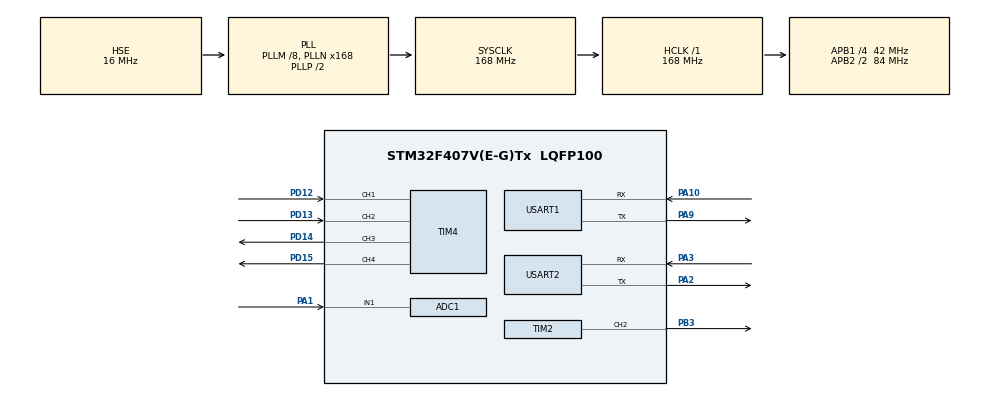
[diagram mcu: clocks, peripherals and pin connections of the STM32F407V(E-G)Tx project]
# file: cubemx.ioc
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ADC1.Channel-1\#ChannelRegularConversion=ADC_CHANNEL_1
ADC1.NbrOfConversionFlag=1
ADC1.Rank-1\#ChannelRegularConversion=1
ADC1.SamplingTime-1\#ChannelRegularConversion=ADC_SAMPLETIME_3CYCLES
ADC1.master=1
Mcu.Family=STM32F4
Mcu.Name=STM32F407V(E-G)Tx
Mcu.Package=LQFP100
NVIC.PriorityGroup=NVIC_PRIORITYGROUP_4
PA0-WKUP.Signal=S_TIM2_CH1_ETR
PA1.Signal=ADCx_IN1
PA10.Mode=Asynchronous
PA10.Signal=USART1_RX
PA13.Mode=Serial_Wire
PA13.Signal=SYS_JTMS-SWDIO
PA14.Mode=Serial_Wire
PA14.Signal=SYS_JTCK-SWCLK
PA2.Mode=Asynchronous
PA2.Signal=USART2_TX
PA3.Mode=Asynchronous
PA3.Signal=USART2_RX
PA9.Mode=Asynchronous
PA9.Signal=USART1_TX
PB3.Signal=S_TIM2_CH2
PD12.Signal=S_TIM4_CH1
PD13.Signal=S_TIM4_CH2
PD14.Signal=S_TIM4_CH3
PD15.Signal=S_TIM4_CH4
PH0-OSC_IN.Mode=HSE-External-Oscillator
PH0-OSC_IN.Signal=RCC_OSC_IN
PH1-OSC_OUT.Mode=HSE-External-Oscillator
PH1-OSC_OUT.Signal=RCC_OSC_OUT
ProjectManager.HeapSize=0x200
ProjectManager.StackSize=0x400
ProjectManager.TargetToolchain=EWARM V8.50
RCC.48MHZClocksFreq_Value=84000000
RCC.AHBFreq_Value=168000000
RCC.APB1CLKDivider=RCC_HCLK_DIV4
RCC.APB1Freq_Value=42000000
RCC.APB1TimFreq_Value=84000000
RCC.APB2CLKDivider=RCC_HCLK_DIV2
RCC.APB2Freq_Value=84000000
RCC.APB2TimFreq_Value=168000000
RCC.CortexFreq_Value=168000000
RCC.HCLKFreq_Value=168000000
RCC.HSE_VALUE=16000000
RCC.HSI_VALUE=16000000
RCC.LSE_VALUE=32768
RCC.PLLM=8
RCC.PLLN=168
RCC.PLLSourceVirtual=RCC_PLLSOURCE_HSE
RCC.RCC_MCO1Source=RCC_MCO1SOURCE_PLLCLK
RCC.RCC_MCO2Source=RCC_MCO2SOURCE_PLLCLK
RCC.SYSCLKFreq_VALUE=168000000
RCC.SYSCLKSource=RCC_SYSCLKSOURCE_PLLCLK
RCC.VCOOutputFreq_Value=336000000
SH.ADCx_IN1.0=ADC1_IN1,IN1
SH.S_TIM2_CH1_ETR.0=TIM2_CH1
SH.S_TIM2_CH2.0=TIM2_CH2,PWM Generation2 CH2
SH.S_TIM4_CH1.0=TIM4_CH1,Encoder_Interface
SH.S_TIM4_CH2.0=TIM4_CH2,Encoder_Interface
SH.S_TIM4_CH3.0=TIM4_CH3,PWM Generation3 CH3
SH.S_TIM4_CH4.0=TIM4_CH4,PWM Generation4 CH4
TIM11.AutoReloadPreload=TIM_AUTORELOAD_PRELOAD_ENABLE
TIM11.Period=100-1
TIM2.Channel-PWM\ Generation2\ CH2=TIM_CHANNEL_2
TIM4.Channel-PWM\ Generation3\ CH3=TIM_CHANNEL_3
TIM4.Channel-PWM\ Generation4\ CH4=TIM_CHANNEL_4
USART1.VirtualMode=VM_ASYNC
USART2.VirtualMode=VM_ASYNC
VP_TIM11_VS_ClockSourceINT.Mode=Enable_Timer
VP_TIM13_VS_ClockSourceINT.Mode=Enable_Timer
VP_TIM2_VS_ClockSourceINT.Mode=Internal
VP_TIM3_VS_ClockSourceINT.Mode=Internal
board=custom

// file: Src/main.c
/* USER CODE BEGIN Header */
/**
  ******************************************************************************
  * @file           : main.c
  * @brief          : Main program body
  ******************************************************************************
  * @attention
  *
  * Copyright (c) 2024 STMicroelectronics.
  * All rights reserved.
  *
  * This software is licensed under terms that can be found in the LICENSE file
  * in the root directory of this software component.
  * If no LICENSE file comes with this software, it is provided AS-IS.
  *
  ******************************************************************************
  */
/* USER CODE END Header */
#include "main.h"

ADC_HandleTypeDef hadc1;

TIM_HandleTypeDef htim2;
TIM_HandleTypeDef htim3;
TIM_HandleTypeDef htim4;
TIM_HandleTypeDef htim11;
TIM_HandleTypeDef htim13;

UART_HandleTypeDef huart1;
UART_HandleTypeDef huart2;

void SystemClock_Config(void);
static void MX_GPIO_Init(void);
static void MX_TIM2_Init(void);
static void MX_USART1_UART_Init(void);
static void MX_TIM3_Init(void);
static void MX_USART2_UART_Init(void);
static void MX_ADC1_Init(void);
static void MX_TIM11_Init(void);
static void MX_TIM13_Init(void);
static void MX_TIM4_Init(void);

__WEAK int main(void)
{

  /* USER CODE BEGIN 1 */
////////
  /* USER CODE END 1 */

  /* MCU Configuration--------------------------------------------------------*/

  /* Reset of all peripherals, Initializes the Flash interface and the Systick. */
  HAL_Init();

  /* USER CODE BEGIN Init */
////////
  /* USER CODE END Init */

  /* Configure the system clock */
  SystemClock_Config();

  /* USER CODE BEGIN SysInit */
////////
  /* USER CODE END SysInit */

  /* Initialize all configured peripherals */
  MX_GPIO_Init();
  MX_TIM2_Init();
  MX_USART1_UART_Init();
  MX_TIM3_Init();
  MX_USART2_UART_Init();
  MX_ADC1_Init();
  MX_TIM11_Init();
  MX_TIM13_Init();
  MX_TIM4_Init();
  /* USER CODE BEGIN 2 */
////////
  /* USER CODE END 2 */

  /* Infinite loop */
  /* USER CODE BEGIN WHILE */
////////  while (1)
////////  {
    /* USER CODE END WHILE */

    /* USER CODE BEGIN 3 */
////////  }
  /* USER CODE END 3 */
}

void SystemClock_Config(void)
{
  RCC_OscInitTypeDef RCC_OscInitStruct = {0};
  RCC_ClkInitTypeDef RCC_ClkInitStruct = {0};

  /** Configure the main internal regulator output voltage
  */
  __HAL_RCC_PWR_CLK_ENABLE();
  __HAL_PWR_VOLTAGESCALING_CONFIG(PWR_REGULATOR_VOLTAGE_SCALE1);

  /** Initializes the RCC Oscillators according to the specified parameters
  * in the RCC_OscInitTypeDef structure.
  */
  RCC_OscInitStruct.OscillatorType = RCC_OSCILLATORTYPE_HSE;
  RCC_OscInitStruct.HSEState = RCC_HSE_ON;
  RCC_OscInitStruct.PLL.PLLState = RCC_PLL_ON;
  RCC_OscInitStruct.PLL.PLLSource = RCC_PLLSOURCE_HSE;
  RCC_OscInitStruct.PLL.PLLM = 8;
  RCC_OscInitStruct.PLL.PLLN = 168;
  RCC_OscInitStruct.PLL.PLLP = RCC_PLLP_DIV2;
  RCC_OscInitStruct.PLL.PLLQ = 4;
  if (HAL_RCC_OscConfig(&RCC_OscInitStruct) != HAL_OK)
  {
    Error_Handler();
  }

  /** Initializes the CPU, AHB and APB buses clocks
  */
  RCC_ClkInitStruct.ClockType = RCC_CLOCKTYPE_HCLK|RCC_CLOCKTYPE_SYSCLK
                              |RCC_CLOCKTYPE_PCLK1|RCC_CLOCKTYPE_PCLK2;
  RCC_ClkInitStruct.SYSCLKSource = RCC_SYSCLKSOURCE_PLLCLK;
  RCC_ClkInitStruct.AHBCLKDivider = RCC_SYSCLK_DIV1;
  RCC_ClkInitStruct.APB1CLKDivider = RCC_HCLK_DIV4;
  RCC_ClkInitStruct.APB2CLKDivider = RCC_HCLK_DIV2;

  if (HAL_RCC_ClockConfig(&RCC_ClkInitStruct, FLASH_LATENCY_5) != HAL_OK)
  {
    Error_Handler();
  }
}

static void MX_ADC1_Init(void)
{

  ADC_ChannelConfTypeDef sConfig = {0};

  /** Configure the global features of the ADC (Clock, Resolution, Data Alignment and number of conversion)
  */
  hadc1.Instance = ADC1;
  hadc1.Init.ClockPrescaler = ADC_CLOCK_SYNC_PCLK_DIV4;
  hadc1.Init.Resolution = ADC_RESOLUTION_12B;
  hadc1.Init.ScanConvMode = DISABLE;
  hadc1.Init.ContinuousConvMode = DISABLE;
  hadc1.Init.DiscontinuousConvMode = DISABLE;
  hadc1.Init.ExternalTrigConvEdge = ADC_EXTERNALTRIGCONVEDGE_NONE;
  hadc1.Init.ExternalTrigConv = ADC_SOFTWARE_START;
  hadc1.Init.DataAlign = ADC_DATAALIGN_RIGHT;
  hadc1.Init.NbrOfConversion = 1;
  hadc1.Init.DMAContinuousRequests = DISABLE;
  hadc1.Init.EOCSelection = ADC_EOC_SINGLE_CONV;
  if (HAL_ADC_Init(&hadc1) != HAL_OK)
  {
    Error_Handler();
  }

  /** Configure for the selected ADC regular channel its corresponding rank in the sequencer and its sample time.
  */
  sConfig.Channel = ADC_CHANNEL_1;
  sConfig.Rank = 1;
  sConfig.SamplingTime = ADC_SAMPLETIME_3CYCLES;
  if (HAL_ADC_ConfigChannel(&hadc1, &sConfig) != HAL_OK)
  {
    Error_Handler();
  }

}

static void MX_TIM2_Init(void)
{

  TIM_ClockConfigTypeDef sClockSourceConfig = {0};
  TIM_MasterConfigTypeDef sMasterConfig = {0};
  TIM_OC_InitTypeDef sConfigOC = {0};

  htim2.Instance = TIM2;
  htim2.Init.Prescaler = 0;
  htim2.Init.CounterMode = TIM_COUNTERMODE_UP;
  htim2.Init.Period = 4294967295;
  htim2.Init.ClockDivision = TIM_CLOCKDIVISION_DIV1;
  htim2.Init.AutoReloadPreload = TIM_AUTORELOAD_PRELOAD_DISABLE;
  if (HAL_TIM_Base_Init(&htim2) != HAL_OK)
  {
    Error_Handler();
  }
  sClockSourceConfig.ClockSource = TIM_CLOCKSOURCE_INTERNAL;
  if (HAL_TIM_ConfigClockSource(&htim2, &sClockSourceConfig) != HAL_OK)
  {
    Error_Handler();
  }
  if (HAL_TIM_PWM_Init(&htim2) != HAL_OK)
  {
    Error_Handler();
  }
  sMasterConfig.MasterOutputTrigger = TIM_TRGO_RESET;
  sMasterConfig.MasterSlaveMode = TIM_MASTERSLAVEMODE_DISABLE;
  if (HAL_TIMEx_MasterConfigSynchronization(&htim2, &sMasterConfig) != HAL_OK)
  {
    Error_Handler();
  }
  sConfigOC.OCMode = TIM_OCMODE_PWM1;
  sConfigOC.Pulse = 0;
  sConfigOC.OCPolarity = TIM_OCPOLARITY_HIGH;
  sConfigOC.OCFastMode = TIM_OCFAST_DISABLE;
  if (HAL_TIM_PWM_ConfigChannel(&htim2, &sConfigOC, TIM_CHANNEL_2) != HAL_OK)
  {
    Error_Handler();
  }
  HAL_TIM_MspPostInit(&htim2);

}

static void MX_TIM3_Init(void)
{

  TIM_ClockConfigTypeDef sClockSourceConfig = {0};
  TIM_MasterConfigTypeDef sMasterConfig = {0};

  htim3.Instance = TIM3;
  htim3.Init.Prescaler = 0;
  htim3.Init.CounterMode = TIM_COUNTERMODE_UP;
  htim3.Init.Period = 65535;
  htim3.Init.ClockDivision = TIM_CLOCKDIVISION_DIV1;
  htim3.Init.AutoReloadPreload = TIM_AUTORELOAD_PRELOAD_DISABLE;
  if (HAL_TIM_Base_Init(&htim3) != HAL_OK)
  {
    Error_Handler();
  }
  sClockSourceConfig.ClockSource = TIM_CLOCKSOURCE_INTERNAL;
  if (HAL_TIM_ConfigClockSource(&htim3, &sClockSourceConfig) != HAL_OK)
  {
    Error_Handler();
  }
  sMasterConfig.MasterOutputTrigger = TIM_TRGO_RESET;
  sMasterConfig.MasterSlaveMode = TIM_MASTERSLAVEMODE_DISABLE;
  if (HAL_TIMEx_MasterConfigSynchronization(&htim3, &sMasterConfig) != HAL_OK)
  {
    Error_Handler();
  }

}

static void MX_TIM4_Init(void)
{

  TIM_Encoder_InitTypeDef sConfig = {0};
  TIM_MasterConfigTypeDef sMasterConfig = {0};
  TIM_OC_InitTypeDef sConfigOC = {0};

  htim4.Instance = TIM4;
  htim4.Init.Prescaler = 0;
  htim4.Init.CounterMode = TIM_COUNTERMODE_UP;
  htim4.Init.Period = 65535;
  htim4.Init.ClockDivision = TIM_CLOCKDIVISION_DIV1;
  htim4.Init.AutoReloadPreload = TIM_AUTORELOAD_PRELOAD_DISABLE;
  if (HAL_TIM_PWM_Init(&htim4) != HAL_OK)
  {
    Error_Handler();
  }
  sConfig.EncoderMode = TIM_ENCODERMODE_TI1;
  sConfig.IC1Polarity = TIM_ICPOLARITY_RISING;
  sConfig.IC1Selection = TIM_ICSELECTION_DIRECTTI;
  sConfig.IC1Prescaler = TIM_ICPSC_DIV1;
  sConfig.IC1Filter = 0;
  sConfig.IC2Polarity = TIM_ICPOLARITY_RISING;
  sConfig.IC2Selection = TIM_ICSELECTION_DIRECTTI;
  sConfig.IC2Prescaler = TIM_ICPSC_DIV1;
  sConfig.IC2Filter = 0;
  if (HAL_TIM_Encoder_Init(&htim4, &sConfig) != HAL_OK)
  {
    Error_Handler();
  }
  sMasterConfig.MasterOutputTrigger = TIM_TRGO_RESET;
  sMasterConfig.MasterSlaveMode = TIM_MASTERSLAVEMODE_DISABLE;
  if (HAL_TIMEx_MasterConfigSynchronization(&htim4, &sMasterConfig) != HAL_OK)
  {
    Error_Handler();
  }
  sConfigOC.OCMode = TIM_OCMODE_PWM1;
  sConfigOC.Pulse = 0;
  sConfigOC.OCPolarity = TIM_OCPOLARITY_HIGH;
  sConfigOC.OCFastMode = TIM_OCFAST_DISABLE;
  if (HAL_TIM_PWM_ConfigChannel(&htim4, &sConfigOC, TIM_CHANNEL_3) != HAL_OK)
  {
    Error_Handler();
  }
  if (HAL_TIM_PWM_ConfigChannel(&htim4, &sConfigOC, TIM_CHANNEL_4) != HAL_OK)
  {
    Error_Handler();
  }
  HAL_TIM_MspPostInit(&htim4);

}

static void MX_TIM11_Init(void)
{

  htim11.Instance = TIM11;
  htim11.Init.Prescaler = 0;
  htim11.Init.CounterMode = TIM_COUNTERMODE_UP;
  htim11.Init.Period = 100-1;
  htim11.Init.ClockDivision = TIM_CLOCKDIVISION_DIV1;
  htim11.Init.AutoReloadPreload = TIM_AUTORELOAD_PRELOAD_ENABLE;
  if (HAL_TIM_Base_Init(&htim11) != HAL_OK)
  {
    Error_Handler();
  }

}

static void MX_TIM13_Init(void)
{

  htim13.Instance = TIM13;
  htim13.Init.Prescaler = 0;
  htim13.Init.CounterMode = TIM_COUNTERMODE_UP;
  htim13.Init.Period = 65535;
  htim13.Init.ClockDivision = TIM_CLOCKDIVISION_DIV1;
  htim13.Init.AutoReloadPreload = TIM_AUTORELOAD_PRELOAD_DISABLE;
  if (HAL_TIM_Base_Init(&htim13) != HAL_OK)
  {
    Error_Handler();
  }

}

static void MX_USART1_UART_Init(void)
{

  huart1.Instance = USART1;
  huart1.Init.BaudRate = 115200;
  huart1.Init.WordLength = UART_WORDLENGTH_8B;
  huart1.Init.StopBits = UART_STOPBITS_1;
  huart1.Init.Parity = UART_PARITY_NONE;
  huart1.Init.Mode = UART_MODE_TX_RX;
  huart1.Init.HwFlowCtl = UART_HWCONTROL_NONE;
  huart1.Init.OverSampling = UART_OVERSAMPLING_16;
  if (HAL_UART_Init(&huart1) != HAL_OK)
  {
    Error_Handler();
  }

}

static void MX_USART2_UART_Init(void)
{

  huart2.Instance = USART2;
  huart2.Init.BaudRate = 115200;
  huart2.Init.WordLength = UART_WORDLENGTH_8B;
  huart2.Init.StopBits = UART_STOPBITS_1;
  huart2.Init.Parity = UART_PARITY_NONE;
  huart2.Init.Mode = UART_MODE_TX_RX;
  huart2.Init.HwFlowCtl = UART_HWCONTROL_NONE;
  huart2.Init.OverSampling = UART_OVERSAMPLING_16;
  if (HAL_UART_Init(&huart2) != HAL_OK)
  {
    Error_Handler();
  }

}

static void MX_GPIO_Init(void)
{

  /* GPIO Ports Clock Enable */
  __HAL_RCC_GPIOH_CLK_ENABLE();
  __HAL_RCC_GPIOA_CLK_ENABLE();
  __HAL_RCC_GPIOD_CLK_ENABLE();
  __HAL_RCC_GPIOB_CLK_ENABLE();

}

void Error_Handler(void)
{
  __disable_irq();
  while (1)
  {
  }
}
